# STM32WL3R register map
File version: 1.0
CPU: CM0+ r0p0, little endian, MPU, no FPU, 4 interrupt priority bits
Registers are 32-bit, read-write, reset 0x0 unless marked. A register's access mark holds for its fields unless they carry their own. Offsets are from the block's base; [hi:lo] are bit positions; {n}, {i} and the like mark numbered series.

## GPIOA — GPIOA address block description
Base 0x48000000
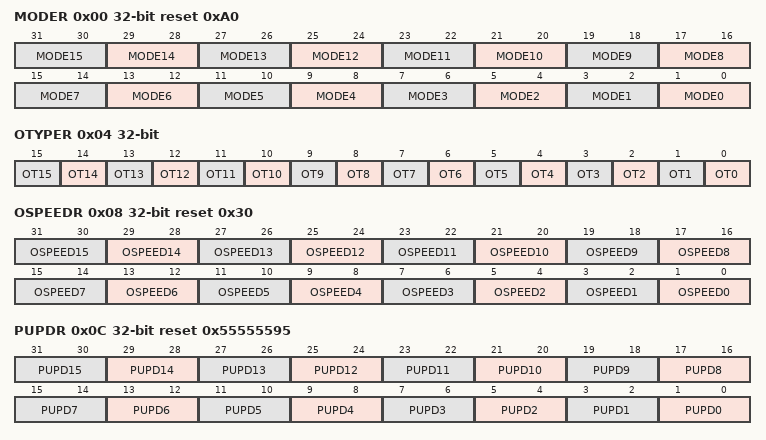
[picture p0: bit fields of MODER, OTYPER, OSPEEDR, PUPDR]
0x00 MODER reset 0xA0
  [2n+1:2n] MODE{n} (n=0..15) — MODE{n}[1:0]Port A configuration bits.
0x04 OTYPER
  [n] OT{n} (n=0..15) — OT{n}: Port A configuration bits
0x08 OSPEEDR reset 0x30
  [2n+1:2n] OSPEED{n} (n=0..15) — OSPEED{n}[1:0]: Port A configuration bits
0x0C PUPDR reset 0x55555595
  [2n+1:2n] PUPD{n} (n=0..15) — PUPD{n}: Port A configuration bits
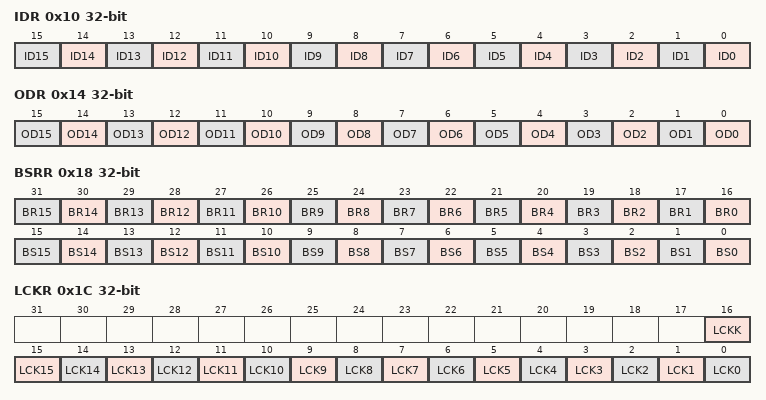
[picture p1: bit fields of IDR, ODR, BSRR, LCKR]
0x10 IDR ro
  [n] ID{n} (n=0..15) — ID{n}: Port A input data bit.
0x14 ODR
  [n] OD{n} (n=0..15) — OD{n}: Port A output data bit
0x18 BSRR wo
  [n+16] BR{n} (n=0..15) — BR{n}: Port A reset bit y
  [n] BS{n} (n=0..15) — BS{n}: Port A set bit y
0x1C LCKR
  [16] LCKK — LCKK: Lock key
  [n] LCK{n} (n=0..15) — LCK{n}: Port A lock bit {n}
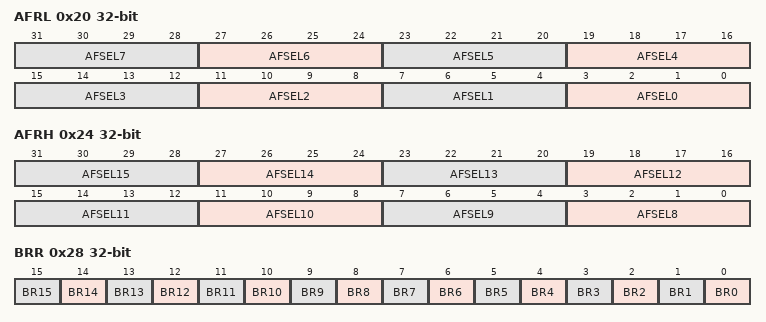
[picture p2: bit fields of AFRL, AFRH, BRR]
0x20 AFRL
  [4n+3:4n] AFSEL{n} (n=0..7) — y[3:0]: Alternate function selection for port A pin y (y = 0.
0x24 AFRH
  [4n-29:4n-32] AFSEL{n} (n=8..15) — y[3:0]: Alternate function selection for port A pin y (y = 8.
0x28 BRR
  [n] BR{n} wo (n=0..15) — BR{n}: Port A reset bit y (y = 0.

## GPIOB — GPIOB address block description
Base 0x48100000
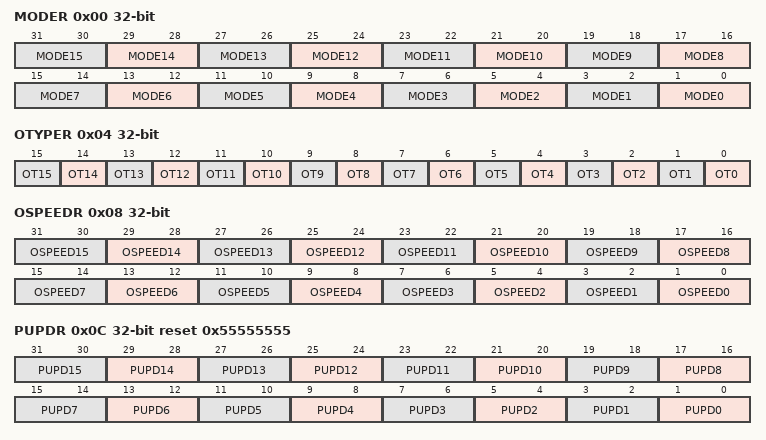
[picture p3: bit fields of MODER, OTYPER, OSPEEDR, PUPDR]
0x00 MODER
  [2n+1:2n] MODE{n} (n=0..15) — MODE{n}[1:0]Port B configuration bits.
0x04 OTYPER
  [n] OT{n} (n=0..15) — OT{n}: Port B configuration bits
0x08 OSPEEDR
  [2n+1:2n] OSPEED{n} (n=0..15) — OSPEED{n}[1:0]: Port B configuration bits
0x0C PUPDR reset 0x55555555
  [2n+1:2n] PUPD{n} (n=0..15) — PUPD{n}: Port B configuration bits
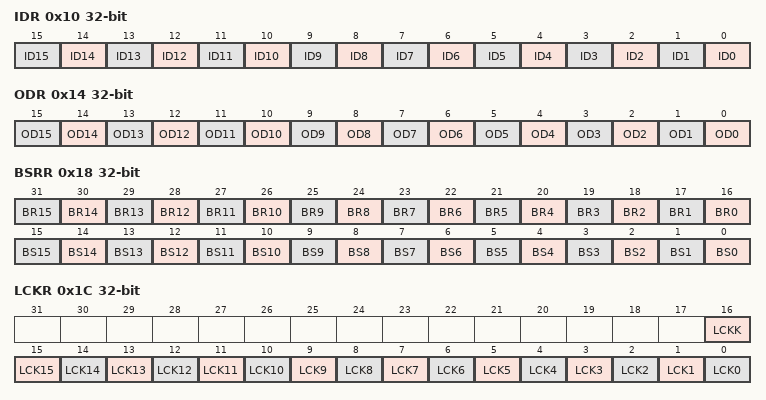
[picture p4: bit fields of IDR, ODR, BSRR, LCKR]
0x10 IDR ro
  [n] ID{n} (n=0..15) — ID{n}: Port B input data bit.
0x14 ODR
  [n] OD{n} (n=0..15) — OD{n}: Port B output data bit
0x18 BSRR wo
  [n+16] BR{n} (n=0..15) — BR{n}: Port B reset bit y
  [n] BS{n} (n=0..15) — BS{n}: Port B set bit y
0x1C LCKR
  [16] LCKK — LCKK: Lock key
  [n] LCK{n} (n=0..15) — LCK{n}: Port B lock bit {n}
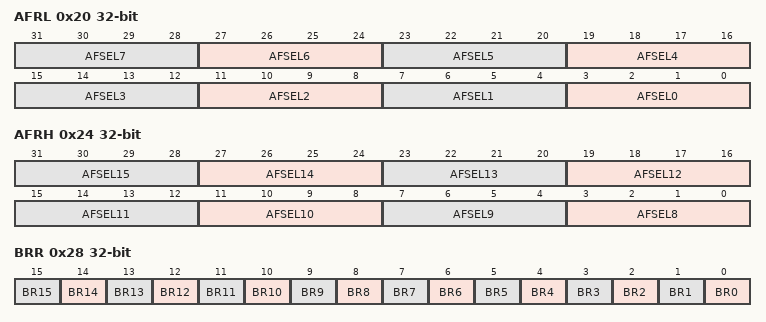
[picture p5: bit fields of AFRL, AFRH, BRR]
0x20 AFRL
  [4n+3:4n] AFSEL{n} (n=0..7) — y[3:0]: Alternate function selection for Port B pin y (y = 0.
0x24 AFRH
  [4n-29:4n-32] AFSEL{n} (n=8..15) — y[3:0]: Alternate function selection for Port B pin y (y = 8.
0x28 BRR
  [n] BR{n} wo (n=0..15) — BR{n}: Port B reset bit y (y = 0.

## I2C1 — I2C1 address block description
Base 0x41000000
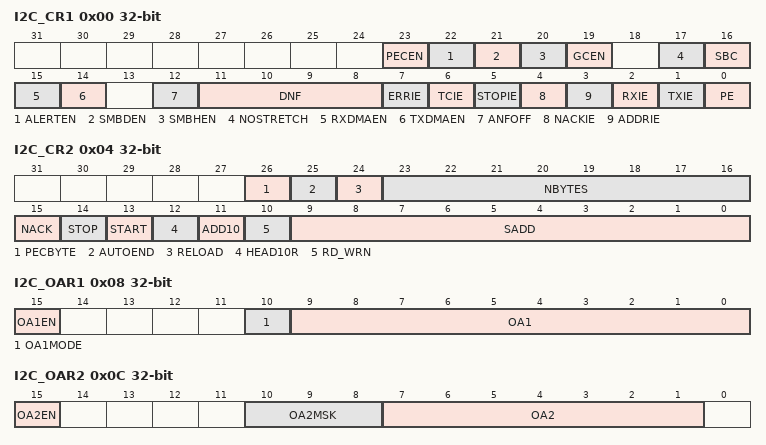
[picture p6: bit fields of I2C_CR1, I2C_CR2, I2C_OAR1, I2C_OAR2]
0x00 I2C_CR1
  [23] PECEN — PEC enable
  [22] ALERTEN — SMBus alert enable
  [21] SMBDEN — SMBus Device Default address enable
  [20] SMBHEN — SMBus Host address enable
  [19] GCEN — General call enable
    0=General call disabled; 1=General call enabled
  [17] NOSTRETCH — Clock stretching disable
  [16] SBC — Slave byte control
  [15] RXDMAEN ro — DMA reception requests enable
  [14] TXDMAEN — DMA transmission requests enable
  [12] ANFOFF — Analog noise filter OFF
  [11:8] DNF — Digital noise filter
  [7] ERRIE — Error interrupts enable
  [6] TCIE — Transfer Complete interrupt enable
  [5] STOPIE — STOP detection Interrupt enable
  [4] NACKIE — Not acknowledge received Interrupt enable
  [3] ADDRIE — Address match Interrupt enable (slave only)
  [2] RXIE — RX Interrupt enable
  [1] TXIE — TX Interrupt enable
  [0] PE — Peripheral enable
0x04 I2C_CR2
  [26] PECBYTE — Packet error checking byte
  [25] AUTOEND — Automatic end mode (master mode)
  [24] RELOAD — NBYTES reload mode
  [23:16] NBYTES — Number of bytes
  [15] NACK — NACK generation (slave mode)
  [14] STOP — Stop generation (master mode)
  [13] START — Start generation
  [12] HEAD10R — Ten bit (10-bit) address header only read direction (master receiver mode)
  [11] ADD10 — Ten-bit addressing mode (master mode)
  [10] RD_WRN — Transfer direction (master mode)
  [9:0] SADD — Slave address
0x08 I2C_OAR1
  [15] OA1EN — Own Address 1 enable
  [10] OA1MODE — Own Address 1 10-bit mode
  [9:0] OA1 — Interface address
0x0C I2C_OAR2
  [15] OA2EN — Own Address 2 enable
    0=Own address 2 disabled; 1=Own address 2 enabled
  [10:8] OA2MSK — Own Address 2 masks
  [7:1] OA2 — Interface address
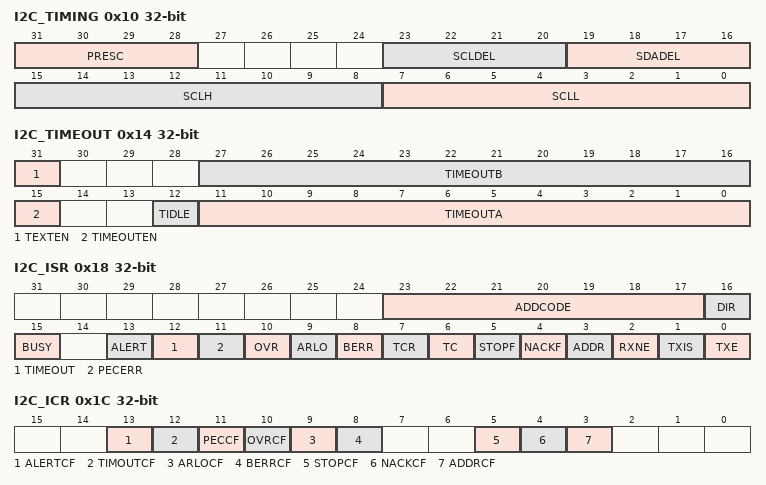
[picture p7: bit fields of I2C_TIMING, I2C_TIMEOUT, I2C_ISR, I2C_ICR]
0x10 I2C_TIMING
  [31:28] PRESC — Timing prescaler
  [23:20] SCLDEL — Data setup time
  [19:16] SDADEL — Data hold time
  [15:8] SCLH — SCL high period (master mode)
  [7:0] SCLL — SCL low period (master mode)
0x14 I2C_TIMEOUT
  [31] TEXTEN — Extended clock timeout enable
  [27:16] TIMEOUTB — Bus timeout B
  [15] TIMEOUTEN — Clock timeout enable
  [12] TIDLE — Idle clock timeout detection
  [11:0] TIMEOUTA — Bus Timeout A
0x18 I2C_ISR
  [23:17] ADDCODE ro — Address match code (Slave mode)
  [16] DIR ro — Transfer direction (Slave mode)
  [15] BUSY ro — Bus busy
  [13] ALERT ro — SMBus alert
  [12] TIMEOUT ro — Timeout or tLOW detection flag
  [11] PECERR ro — PEC Error in reception
  [10] OVR ro — Overrun/Underrun (slave mode)
  [9] ARLO ro — Arbitration lost
  [8] BERR ro — Bus error
  [7] TCR ro — Transfer Complete Reload
  [6] TC ro — Transfer Complete (master mode)
  [5] STOPF ro — Stop detection flag
  [4] NACKF ro — Not Acknowledge received flag
  [3] ADDR ro — Address matched (slave mode)
  [2] RXNE ro — Receive data register not empty (receivers)
  [1] TXIS — Transmit interrupt status (transmitters)
  [0] TXE — Transmit data register empty (transmitters)
0x1C I2C_ICR
  [13] ALERTCF wo — Alert flag clear
  [12] TIMOUTCF wo — Timeout detection flag clear
  [11] PECCF wo — PEC Error flag clear
  [10] OVRCF wo — Overrun/Underrun flag clear
  [9] ARLOCF wo — Arbitration Lost flag clear
  [8] BERRCF wo — Bus error flag clear
  [5] STOPCF wo — Stop detection flag clear
  [4] NACKCF wo — Not Acknowledge flag clear
  [3] ADDRCF wo — Address matched flag clear
0x20 I2C_PEC ro
  [7:0] PEC — Packet error checking register
0x24 I2C_RXDR ro
  [7:0] RXDATA — Eight bit (8-bit) receive data
0x28 I2C_TXDR
  [7:0] TXDATA — Eight bits (8-bit) transmit data
